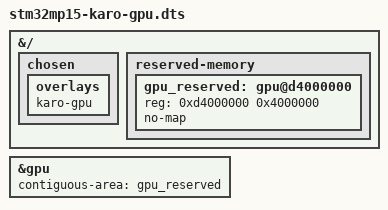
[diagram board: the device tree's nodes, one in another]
// SPDX-License-Identifier: (GPL-2.0-only OR BSD-3-Clause)
/*
 * Copyright (C) 2022 Lothar Waßmann <LW@KARO-electronics.de>
 */

/dts-v1/;

/plugin/;

&{/} {
	chosen {
		overlays {
			karo-gpu;
		};
	};


	reserved-memory {
		gpu_reserved: gpu@d4000000 {
			reg = <0xd4000000 0x4000000>;
			no-map;
		};
	};
};

&gpu {
	contiguous-area = <&gpu_reserved>;
	status = "okay";
};
